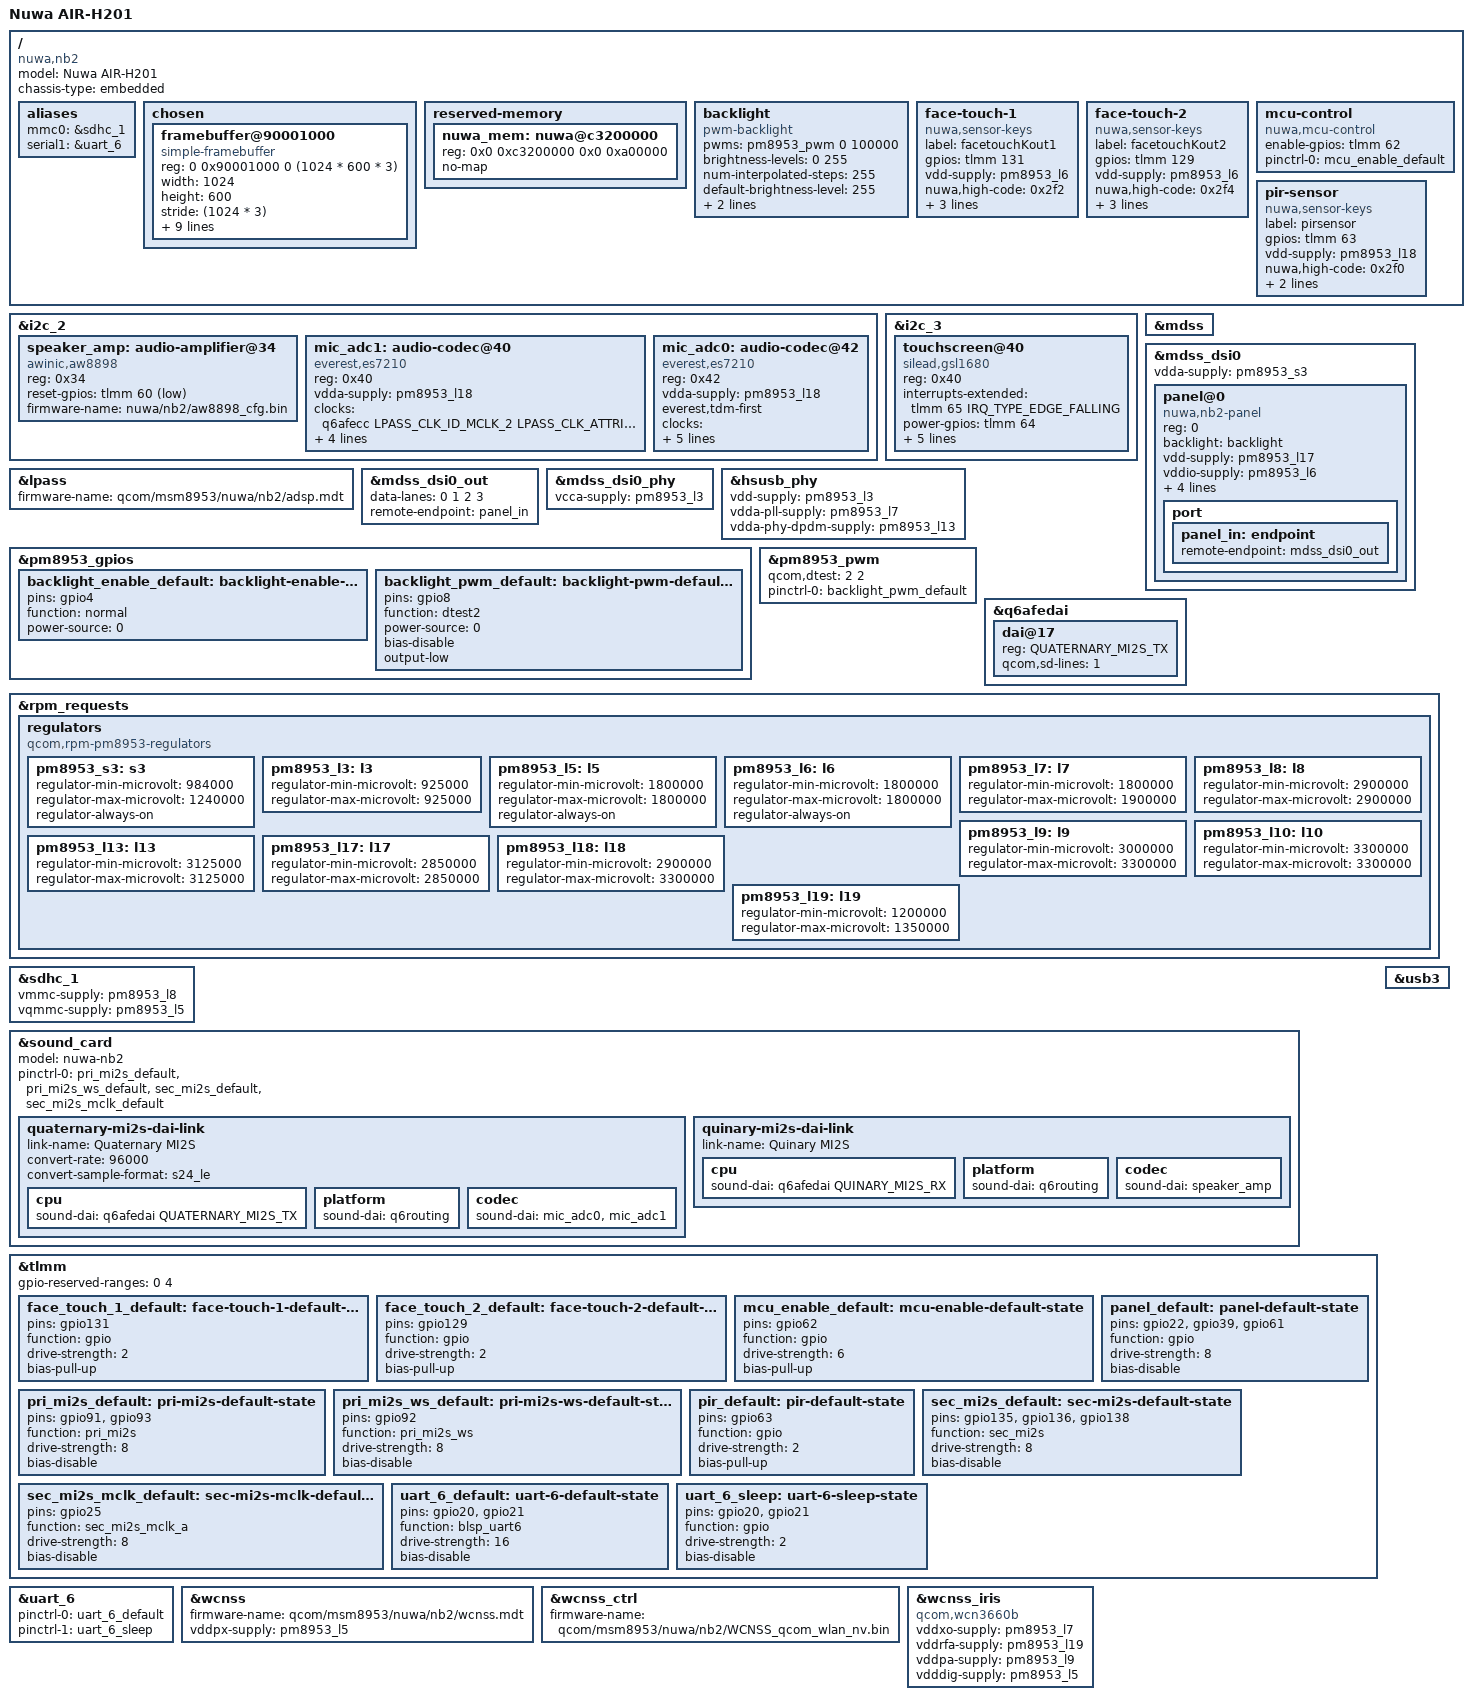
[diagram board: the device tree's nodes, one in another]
// SPDX-License-Identifier: BSD-3-Clause
/dts-v1/;

#include <dt-bindings/input/linux-event-codes.h>
#include "sdm450.dtsi"
#include "pm8953.dtsi"
#include "pmi632.dtsi"

/ {
	model = "Nuwa AIR-H201";
	compatible = "nuwa,nb2", "qcom,sdm450";
	chassis-type = "embedded";

	aliases {
		mmc0 = &sdhc_1;
		serial1 = &uart_6;
	};

	chosen {
		#address-cells = <2>;
		#size-cells = <2>;
		ranges;

		framebuffer@90001000 {
			compatible = "simple-framebuffer";
			reg = <0 0x90001000 0 (1024 * 600 * 3)>;

			width = <1024>;
			height = <600>;
			stride = <(1024 * 3)>;
			format = "r8g8b8";

			power-domains = <&gcc MDSS_GDSC>;

			clocks = <&gcc GCC_MDSS_AHB_CLK>,
				 <&gcc GCC_MDSS_AXI_CLK>,
				 <&gcc GCC_MDSS_VSYNC_CLK>,
				 <&gcc GCC_MDSS_MDP_CLK>,
				 <&gcc GCC_MDSS_BYTE0_CLK>,
				 <&gcc GCC_MDSS_PCLK0_CLK>,
				 <&gcc GCC_MDSS_ESC0_CLK>;
		};
	};

	reserved-memory {
		nuwa_mem: nuwa@c3200000 {
			reg = <0x0 0xc3200000 0x0 0xa00000>;
			no-map;
		};
	};

	backlight: backlight {
		compatible = "pwm-backlight";
		pwms = <&pm8953_pwm 0 100000>;
		brightness-levels = <0 255>;
		num-interpolated-steps = <255>;
		default-brightness-level = <255>;
		enable-gpios = <&pm8953_gpios 4 GPIO_ACTIVE_HIGH>;

		pinctrl-0 = <&backlight_enable_default>;
		pinctrl-names = "default";
	};

	/* Vendor input device names and key codes, kept for the stock key layouts */
	face-touch-1 {
		compatible = "nuwa,sensor-keys";
		label = "facetouchKout1";
		gpios = <&tlmm 131 GPIO_ACTIVE_HIGH>;
		vdd-supply = <&pm8953_l6>;

		nuwa,high-code = <0x2f2>;
		nuwa,low-code = <0x2f3>;
		nuwa,recovery-code = <KEY_VOLUMEUP>;

		pinctrl-0 = <&face_touch_1_default>;
		pinctrl-names = "default";
	};

	face-touch-2 {
		compatible = "nuwa,sensor-keys";
		label = "facetouchKout2";
		gpios = <&tlmm 129 GPIO_ACTIVE_HIGH>;
		vdd-supply = <&pm8953_l6>;

		nuwa,high-code = <0x2f4>;
		nuwa,low-code = <0x2f5>;
		nuwa,recovery-code = <KEY_VOLUMEDOWN>;

		pinctrl-0 = <&face_touch_2_default>;
		pinctrl-names = "default";
	};

	mcu-control {
		compatible = "nuwa,mcu-control";
		enable-gpios = <&tlmm 62 GPIO_ACTIVE_HIGH>;

		pinctrl-0 = <&mcu_enable_default>;
		pinctrl-names = "default";
	};

	pir-sensor {
		compatible = "nuwa,sensor-keys";
		label = "pirsensor";
		gpios = <&tlmm 63 GPIO_ACTIVE_HIGH>;
		vdd-supply = <&pm8953_l18>;

		nuwa,high-code = <0x2f0>;
		nuwa,low-code = <0x2f1>;

		pinctrl-0 = <&pir_default>;
		pinctrl-names = "default";
	};
};

&i2c_2 {
	status = "okay";

	speaker_amp: audio-amplifier@34 {
		compatible = "awinic,aw8898";
		reg = <0x34>;
		reset-gpios = <&tlmm 60 GPIO_ACTIVE_LOW>;
		firmware-name = "nuwa/nb2/aw8898_cfg.bin";
		#sound-dai-cells = <0>;
	};

	mic_adc1: audio-codec@40 {
		compatible = "everest,es7210";
		reg = <0x40>;
		vdda-supply = <&pm8953_l18>;

		clocks = <&q6afecc LPASS_CLK_ID_MCLK_2 LPASS_CLK_ATTRIBUTE_COUPLE_NO>;
		clock-names = "mclk";
		assigned-clocks = <&q6afecc LPASS_CLK_ID_MCLK_2 LPASS_CLK_ATTRIBUTE_COUPLE_NO>;
		assigned-clock-rates = <12288000>;

		#sound-dai-cells = <0>;
		sound-name-prefix = "Mic Array 1";
	};

	mic_adc0: audio-codec@42 {
		compatible = "everest,es7210";
		reg = <0x42>;
		vdda-supply = <&pm8953_l18>;
		everest,tdm-first;

		clocks = <&q6afecc LPASS_CLK_ID_MCLK_2 LPASS_CLK_ATTRIBUTE_COUPLE_NO>;
		clock-names = "mclk";
		assigned-clocks = <&q6afecc LPASS_CLK_ID_MCLK_2 LPASS_CLK_ATTRIBUTE_COUPLE_NO>;
		assigned-clock-rates = <12288000>;

		#sound-dai-cells = <0>;
		sound-name-prefix = "Mic Array 0";
	};
};

&i2c_3 {
	status = "okay";

	touchscreen@40 {
		compatible = "silead,gsl1680";
		reg = <0x40>;

		interrupts-extended = <&tlmm 65 IRQ_TYPE_EDGE_FALLING>;
		power-gpios = <&tlmm 64 GPIO_ACTIVE_HIGH>;
		avdd-supply = <&pm8953_l10>;

		firmware-name = "gslx680-nuwa-nb2.fw";
		touchscreen-size-x = <1024>;
		touchscreen-size-y = <600>;
		silead,max-fingers = <10>;
	};
};

&lpass {
	firmware-name = "qcom/msm8953/nuwa/nb2/adsp.mdt";

	status = "okay";
};

&mdss {
	status = "okay";
};

&mdss_dsi0 {
	vdda-supply = <&pm8953_s3>;

	status = "okay";

	panel@0 {
		/* lk2nd prepends the compatible of the detected panel variant */
		compatible = "nuwa,nb2-panel";
		reg = <0>;

		backlight = <&backlight>;
		vdd-supply = <&pm8953_l17>;
		vddio-supply = <&pm8953_l6>;

		enable-gpios = <&tlmm 39 GPIO_ACTIVE_HIGH>;
		power-gpios = <&tlmm 22 GPIO_ACTIVE_HIGH>;
		reset-gpios = <&tlmm 61 GPIO_ACTIVE_LOW>;

		pinctrl-0 = <&panel_default>;
		pinctrl-names = "default";

		port {
			panel_in: endpoint {
				remote-endpoint = <&mdss_dsi0_out>;
			};
		};
	};
};

&mdss_dsi0_out {
	data-lanes = <0 1 2 3>;
	remote-endpoint = <&panel_in>;
};

&mdss_dsi0_phy {
	vcca-supply = <&pm8953_l3>;

	status = "okay";
};

&hsusb_phy {
	vdd-supply = <&pm8953_l3>;
	vdda-pll-supply = <&pm8953_l7>;
	vdda-phy-dpdm-supply = <&pm8953_l13>;

	status = "okay";
};

&pm8953_gpios {
	backlight_enable_default: backlight-enable-default-state {
		pins = "gpio4";
		function = "normal";
		power-source = <0>;
	};

	backlight_pwm_default: backlight-pwm-default-state {
		pins = "gpio8";
		function = "dtest2";
		power-source = <0>;
		bias-disable;
		output-low;
	};
};

&pm8953_pwm {
	qcom,dtest = <2 2>;

	pinctrl-0 = <&backlight_pwm_default>;
	pinctrl-names = "default";

	status = "okay";
};

&q6afedai {
	dai@17 {
		reg = <QUATERNARY_MI2S_TX>;
		qcom,sd-lines = <1>;
	};
};

&rpm_requests {
	regulators {
		compatible = "qcom,rpm-pm8953-regulators";

		/* Also feeds L1-L3, so it must never be switched off */
		pm8953_s3: s3 {
			regulator-min-microvolt = <984000>;
			regulator-max-microvolt = <1240000>;
			regulator-always-on;
		};

		pm8953_l3: l3 {
			regulator-min-microvolt = <925000>;
			regulator-max-microvolt = <925000>;
		};

		pm8953_l5: l5 {
			regulator-min-microvolt = <1800000>;
			regulator-max-microvolt = <1800000>;
			regulator-always-on;
		};

		/* I/O rail shared with the display and the face sensors */
		pm8953_l6: l6 {
			regulator-min-microvolt = <1800000>;
			regulator-max-microvolt = <1800000>;
			regulator-always-on;
		};

		pm8953_l7: l7 {
			regulator-min-microvolt = <1800000>;
			regulator-max-microvolt = <1900000>;
		};

		pm8953_l8: l8 {
			regulator-min-microvolt = <2900000>;
			regulator-max-microvolt = <2900000>;
		};

		pm8953_l9: l9 {
			regulator-min-microvolt = <3000000>;
			regulator-max-microvolt = <3300000>;
		};

		pm8953_l10: l10 {
			regulator-min-microvolt = <3300000>;
			regulator-max-microvolt = <3300000>;
		};

		pm8953_l13: l13 {
			regulator-min-microvolt = <3125000>;
			regulator-max-microvolt = <3125000>;
		};

		pm8953_l17: l17 {
			regulator-min-microvolt = <2850000>;
			regulator-max-microvolt = <2850000>;
		};

		pm8953_l18: l18 {
			regulator-min-microvolt = <2900000>;
			regulator-max-microvolt = <3300000>;
		};

		pm8953_l19: l19 {
			regulator-min-microvolt = <1200000>;
			regulator-max-microvolt = <1350000>;
		};
	};
};

&sdhc_1 {
	vmmc-supply = <&pm8953_l8>;
	vqmmc-supply = <&pm8953_l5>;

	status = "okay";
};

/* Only external codecs: the amplifier and, later, the microphone ADCs */
&sound_card {
	model = "nuwa-nb2";
	/delete-property/ audio-routing;

	pinctrl-0 = <&pri_mi2s_default>, <&pri_mi2s_ws_default>,
		    <&sec_mi2s_default>, <&sec_mi2s_mclk_default>;
	pinctrl-names = "default";

	status = "okay";

	/delete-node/ primary-mi2s-dai-link;
	/delete-node/ tertiary-mi2s-dai-link;

	/* Both ADCs share one data line in N LRCK TDM mode, as on the stock software */
	quaternary-mi2s-dai-link {
		link-name = "Quaternary MI2S";
		convert-rate = <96000>;
		convert-sample-format = "s24_le";

		cpu {
			sound-dai = <&q6afedai QUATERNARY_MI2S_TX>;
		};

		platform {
			sound-dai = <&q6routing>;
		};

		codec {
			sound-dai = <&mic_adc0>, <&mic_adc1>;
		};
	};

	quinary-mi2s-dai-link {
		link-name = "Quinary MI2S";

		cpu {
			sound-dai = <&q6afedai QUINARY_MI2S_RX>;
		};

		platform {
			sound-dai = <&q6routing>;
		};

		codec {
			sound-dai = <&speaker_amp>;
		};
	};
};

&tlmm {
	gpio-reserved-ranges = <0 4>;

	face_touch_1_default: face-touch-1-default-state {
		pins = "gpio131";
		function = "gpio";
		drive-strength = <2>;
		bias-pull-up;
	};

	face_touch_2_default: face-touch-2-default-state {
		pins = "gpio129";
		function = "gpio";
		drive-strength = <2>;
		bias-pull-up;
	};

	mcu_enable_default: mcu-enable-default-state {
		pins = "gpio62";
		function = "gpio";
		drive-strength = <6>;
		bias-pull-up;
	};

	panel_default: panel-default-state {
		pins = "gpio22", "gpio39", "gpio61";
		function = "gpio";
		drive-strength = <8>;
		bias-disable;
	};

	pri_mi2s_default: pri-mi2s-default-state {
		pins = "gpio91", "gpio93";
		function = "pri_mi2s";
		drive-strength = <8>;
		bias-disable;
	};

	pri_mi2s_ws_default: pri-mi2s-ws-default-state {
		pins = "gpio92";
		function = "pri_mi2s_ws";
		drive-strength = <8>;
		bias-disable;
	};

	pir_default: pir-default-state {
		pins = "gpio63";
		function = "gpio";
		drive-strength = <2>;
		bias-pull-up;
	};

	sec_mi2s_default: sec-mi2s-default-state {
		pins = "gpio135", "gpio136", "gpio138";
		function = "sec_mi2s";
		drive-strength = <8>;
		bias-disable;
	};

	sec_mi2s_mclk_default: sec-mi2s-mclk-default-state {
		pins = "gpio25";
		function = "sec_mi2s_mclk_a";
		drive-strength = <8>;
		bias-disable;
	};

	/* Only TX and RX: GPIO 22 is a display power switch */
	uart_6_default: uart-6-default-state {
		pins = "gpio20", "gpio21";
		function = "blsp_uart6";
		drive-strength = <16>;
		bias-disable;
	};

	uart_6_sleep: uart-6-sleep-state {
		pins = "gpio20", "gpio21";
		function = "gpio";
		drive-strength = <2>;
		bias-disable;
	};
};

/* The motion controller link */
&uart_6 {
	pinctrl-0 = <&uart_6_default>;
	pinctrl-1 = <&uart_6_sleep>;
	pinctrl-names = "default", "sleep";

	status = "okay";
};

&usb3 {
	status = "okay";
};

&wcnss {
	firmware-name = "qcom/msm8953/nuwa/nb2/wcnss.mdt";
	vddpx-supply = <&pm8953_l5>;

	status = "okay";
};

&wcnss_ctrl {
	firmware-name = "qcom/msm8953/nuwa/nb2/WCNSS_qcom_wlan_nv.bin";
};

&wcnss_iris {
	compatible = "qcom,wcn3660b";

	vddxo-supply = <&pm8953_l7>;
	vddrfa-supply = <&pm8953_l19>;
	vddpa-supply = <&pm8953_l9>;
	vdddig-supply = <&pm8953_l5>;
};
